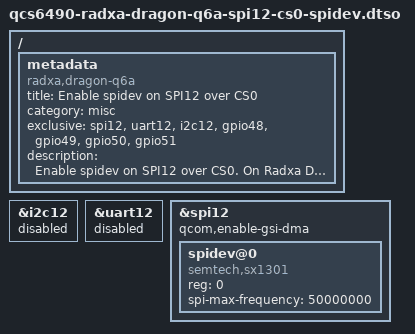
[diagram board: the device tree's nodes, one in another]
// SPDX-License-Identifier: BSD-3-Clause
/*
 * Copyright (c) 2025 Radxa Computer (Shenzhen) Co., Ltd.
 */

/dts-v1/;
/plugin/;

/ {
    metadata {
        title = "Enable spidev on SPI12 over CS0";
        compatible = "radxa,dragon-q6a";
        category = "misc";
        exclusive = "spi12", "uart12", "i2c12", "gpio48", "gpio49", "gpio50", "gpio51";
        description = "Enable spidev on SPI12 over CS0. 
On Radxa Dragon Q6A, this is pin 19(mosi), 21(miso), 23(sclk), 24(cs0).";
    };
};

&i2c12 {
	status = "disabled";
};

&uart12 {
	status = "disabled";
};

&spi12 {
	qcom,enable-gsi-dma;
	status = "okay";
	
	spidev@0 {
		compatible = "semtech,sx1301";
		status = "okay";
		reg = <0>;
		spi-max-frequency = <50000000>;
	};
};
